# nrf52 register map
Vendor: Nordic Semiconductor; Series: nrf52; File version: 1
CPU: CM4 r0p1, little endian, MPU, FPU, 3 interrupt priority bits
Registers are 32-bit, read-write, reset 0x0 unless marked. A register's access mark holds for its fields unless they carry their own. Offsets are from the block's base; [hi:lo] are bit positions; {n}, {i} and the like mark numbered series.

## SWI0 — Software interrupt 0
Base 0x40014000
Same registers: SWI1 0x40015000, SWI2 0x40016000, SWI3 0x40017000, SWI4 0x40018000, SWI5 0x40019000

## EGU0 — Event Generator Unit 0
Base 0x40014000; alternate view of SWI0
Same registers: EGU1 0x40015000 (alternate view of SWI1), EGU2 0x40016000 (alternate view of SWI2), EGU3 0x40017000 (alternate view of SWI3), EGU4 0x40018000 (alternate view of SWI4), EGU5 0x40019000 (alternate view of SWI5)
{0x0+4i} TASKS_TRIGGER[{i}] (i=0..15) wo — Description collection[0]: Trigger 0 for triggering the corresponding TRIGGERED[0] event
  [0] TASKS_TRIGGER
{0x100+4i} EVENTS_TRIGGERED[{i}] (i=0..15) — Description collection[0]: Event number 0 generated by triggering the corresponding TRIGGER[0] task
  [0] EVENTS_TRIGGERED
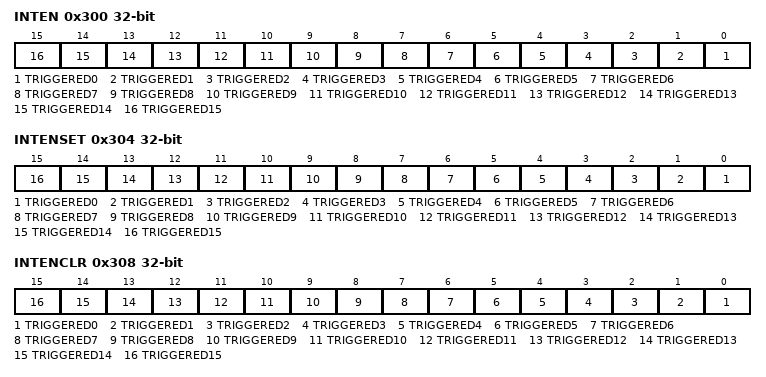
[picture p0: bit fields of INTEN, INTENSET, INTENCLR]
0x300 INTEN — Enable or disable interrupt
  [all] fields
    0=Disabled; 1=Enabled
  [n] TRIGGERED{n} (n=0..15) — Enable or disable interrupt for TRIGGERED[{n}] event
0x304 INTENSET — Enable interrupt
  [all] fields
    on read: 0=Disabled (Read: Disabled); 1=Enabled (Read: Enabled) | on write: 1=Set (Enable)
  [n] TRIGGERED{n} (n=0..15) — Write '1' to Enable interrupt for TRIGGERED[{n}] event
0x308 INTENCLR — Disable interrupt
  [all] fields
    on read: 0=Disabled (Read: Disabled); 1=Enabled (Read: Enabled) | on write: 1=Clear (Disable)
  [n] TRIGGERED{n} (n=0..15) — Write '1' to Disable interrupt for TRIGGERED[{n}] event

## TIMER3 — Timer/Counter 3
Base 0x4001A000
Same registers: TIMER4 0x4001B000
0x00 TASKS_START wo — Start Timer
  [0] TASKS_START
0x04 TASKS_STOP wo — Stop Timer
  [0] TASKS_STOP
0x08 TASKS_COUNT wo — Increment Timer (Counter mode only)
  [0] TASKS_COUNT
0x0C TASKS_CLEAR wo — Clear time
  [0] TASKS_CLEAR
0x10 TASKS_SHUTDOWN wo — Deprecated register - Shut down timer
  [0] TASKS_SHUTDOWN
{0x40+4i} TASKS_CAPTURE[{i}] (i=0..5) wo — Description collection[0]: Capture Timer value to CC[0] register
  [0] TASKS_CAPTURE
{0x140+4i} EVENTS_COMPARE[{i}] (i=0..5) — Description collection[0]: Compare event on CC[0] match
  [0] EVENTS_COMPARE
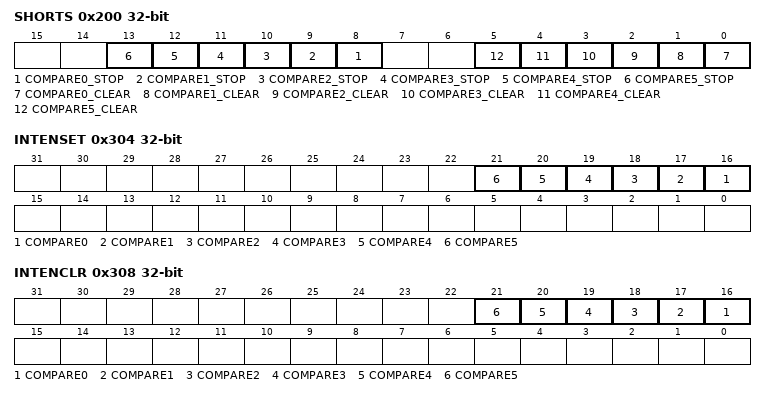
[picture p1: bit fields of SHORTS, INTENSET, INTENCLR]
0x200 SHORTS — Shortcut register
  [all] fields
    0=Disabled (Disable shortcut); 1=Enabled (Enable shortcut)
  [n+8] COMPARE{n}_STOP (n=0..5) — Shortcut between COMPARE[{n}] event and STOP task
  [n] COMPARE{n}_CLEAR (n=0..5) — Shortcut between COMPARE[{n}] event and CLEAR task
0x304 INTENSET — Enable interrupt
  [all] fields
    on read: 0=Disabled (Read: Disabled); 1=Enabled (Read: Enabled) | on write: 1=Set (Enable)
  [n+16] COMPARE{n} (n=0..5) — Write '1' to Enable interrupt for COMPARE[{n}] event
0x308 INTENCLR — Disable interrupt
  [all] fields
    on read: 0=Disabled (Read: Disabled); 1=Enabled (Read: Enabled) | on write: 1=Clear (Disable)
  [n+16] COMPARE{n} (n=0..5) — Write '1' to Disable interrupt for COMPARE[{n}] event
0x504 MODE — Timer mode selection
  [1:0] MODE — Timer mode
    0=Timer (Select Timer mode); 1=Counter (Deprecated enumerator - Select Counter mode); 2=LowPowerCounter (Select Low Power Counter mode)
0x508 BITMODE — Configure the number of bits used by the TIMER
  [1:0] BITMODE — Timer bit width
    0=16 bit timer bit width; 1=08Bit (8 bit timer bit width); 2=24 bit timer bit width; 3=32 bit timer bit width
0x510 PRESCALER reset 0x4 — Timer prescaler register
  [3:0] PRESCALER — Prescaler value
{0x540+4i} CC[{i}] (i=0..5) — Description collection[0]: Capture/Compare register 0
  [31:0] CC — Capture/Compare value

## NVMC — Non Volatile Memory Controller
Base 0x4001E000
0x400 READY ro — Ready flag
  [0] READY — NVMC is ready or busy
    0=Busy (NVMC is busy (on-going write or erase operation)); 1=Ready (NVMC is ready)
0x504 CONFIG — Configuration register
  [1:0] WEN — Program memory access mode. It is strongly recommended to only activate erase and write modes when they are actively used. Enabling write or erase will invalidate the cache and keep it invalidated.
    0=Ren (Read only access); 1=Wen (Write Enabled); 2=Een (Erase enabled)
0x508 ERASEPAGE — Register for erasing a page in Code area
  [31:0] ERASEPAGE — Register for starting erase of a page in Code area
0x508 ERASEPCR1 (alternate view of ERASEPAGE) — Deprecated register - Register for erasing a page in Code area. Equivalent to ERASEPAGE.
  [31:0] ERASEPCR1 — Register for erasing a page in Code area. Equivalent to ERASEPAGE.
0x50C ERASEALL — Register for erasing all non-volatile user memory
  [0] ERASEALL — Erase all non-volatile memory including UICR registers. Note that code erase has to be enabled by CONFIG.EEN before the UICR can be erased.
    0=NoOperation; 1=Erase (Start chip erase)
0x510 ERASEPCR0 — Deprecated register - Register for erasing a page in Code area. Equivalent to ERASEPAGE.
  [31:0] ERASEPCR0 — Register for starting erase of a page in Code area. Equivalent to ERASEPAGE.
0x514 ERASEUICR — Register for erasing User Information Configuration Registers
  [0] ERASEUICR — Register starting erase of all User Information Configuration Registers. Note that code erase has to be enabled by CONFIG.EEN before the UICR can be erased.
    0=NoOperation; 1=Erase (Start erase of UICR)
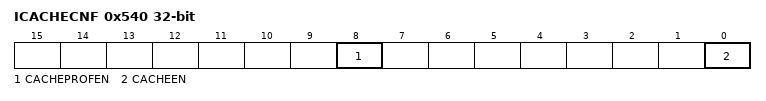
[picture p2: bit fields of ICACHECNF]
0x540 ICACHECNF — I-Code cache configuration register.
  [8] CACHEPROFEN — Cache profiling enable
    0=Disabled (Disable cache profiling); 1=Enabled (Enable cache profiling)
  [0] CACHEEN — Cache enable
    0=Disabled (Disable cache. Invalidates all cache entries.); 1=Enabled (Enable cache)
0x548 IHIT — I-Code cache hit counter.
  [31:0] HITS — Number of cache hits
0x54C IMISS — I-Code cache miss counter.
  [31:0] MISSES — Number of cache misses
